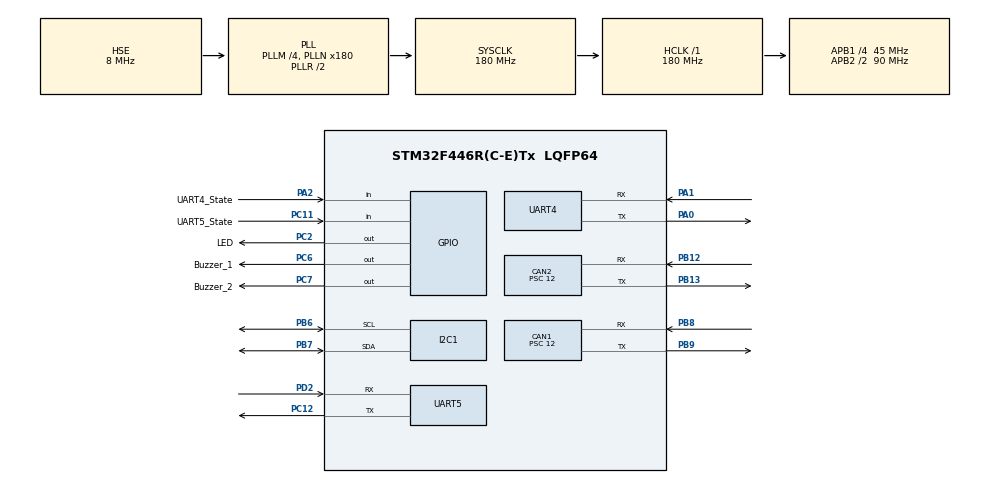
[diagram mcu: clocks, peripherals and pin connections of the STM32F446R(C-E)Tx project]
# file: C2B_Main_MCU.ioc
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CAN1.BS1=CAN_BS1_12TQ
CAN1.BS2=CAN_BS2_2TQ
CAN1.CalculateBaudRate=250000
CAN1.CalculateTimeBit=4000
CAN1.CalculateTimeQuantum=266.66666666666663
CAN1.Prescaler=12
CAN2.BS1=CAN_BS1_11TQ
CAN2.BS2=CAN_BS2_3TQ
CAN2.CalculateBaudRate=250000
CAN2.CalculateTimeBit=4000
CAN2.CalculateTimeQuantum=266.66666666666663
CAN2.Prescaler=12
Mcu.Family=STM32F4
Mcu.Name=STM32F446R(C-E)Tx
Mcu.Package=LQFP64
NVIC.CAN1_RX0_IRQn=true\:0\:0\:false\:false\:true\:true\:true\:true
NVIC.CAN1_RX1_IRQn=true\:0\:0\:false\:false\:true\:true\:true\:true
NVIC.CAN2_RX0_IRQn=true\:0\:0\:false\:false\:true\:true\:true\:true
NVIC.CAN2_RX1_IRQn=true\:0\:0\:false\:false\:true\:true\:true\:true
NVIC.I2C1_ER_IRQn=true\:0\:0\:false\:false\:true\:true\:true\:true
NVIC.I2C1_EV_IRQn=true\:0\:0\:false\:false\:true\:true\:true\:true
NVIC.PriorityGroup=NVIC_PRIORITYGROUP_4
NVIC.TIM8_TRG_COM_TIM14_IRQn=true\:0\:0\:false\:false\:true\:true\:true\:true
NVIC.UART4_IRQn=true\:0\:0\:false\:false\:true\:true\:true\:true
NVIC.UART5_IRQn=true\:0\:0\:false\:false\:true\:true\:true\:true
PA0-WKUP.Mode=Asynchronous
PA0-WKUP.Signal=UART4_TX
PA1.Mode=Asynchronous
PA1.Signal=UART4_RX
PA13.Mode=Serial_Wire
PA13.Signal=SYS_JTMS-SWDIO
PA14.Mode=Serial_Wire
PA14.Signal=SYS_JTCK-SWCLK
PA2.GPIO_Label=UART4_State
PA2.Signal=GPIO_Input
PB12.Mode=CAN_Activate
PB12.Signal=CAN2_RX
PB13.Mode=CAN_Activate
PB13.Signal=CAN2_TX
PB6.Mode=I2C
PB6.Signal=I2C1_SCL
PB7.Mode=I2C
PB7.Signal=I2C1_SDA
PB8.Mode=CAN_Activate
PB8.Signal=CAN1_RX
PB9.Mode=CAN_Activate
PB9.Signal=CAN1_TX
PC11.GPIO_Label=UART5_State
PC11.Signal=GPIO_Input
PC12.Mode=Asynchronous
PC12.Signal=UART5_TX
PC14-OSC32_IN.Mode=LSE-External-Oscillator
PC14-OSC32_IN.Signal=RCC_OSC32_IN
PC15-OSC32_OUT.Mode=LSE-External-Oscillator
PC15-OSC32_OUT.Signal=RCC_OSC32_OUT
PC2.GPIO_Label=LED
PC2.GPIO_Speed=GPIO_SPEED_FREQ_MEDIUM
PC2.Signal=GPIO_Output
PC6.GPIO_Label=Buzzer_1
PC6.Signal=GPIO_Output
PC7.GPIO_Label=Buzzer_2
PC7.Signal=GPIO_Output
PD2.Mode=Asynchronous
PD2.Signal=UART5_RX
PH0-OSC_IN.Mode=HSE-External-Oscillator
PH0-OSC_IN.Signal=RCC_OSC_IN
PH1-OSC_OUT.Mode=HSE-External-Oscillator
PH1-OSC_OUT.Signal=RCC_OSC_OUT
ProjectManager.HeapSize=0x200
ProjectManager.StackSize=0x400
ProjectManager.TargetToolchain=MDK-ARM V5.32
RCC.AHBFreq_Value=180000000
RCC.APB1CLKDivider=RCC_HCLK_DIV4
RCC.APB1Freq_Value=45000000
RCC.APB1TimFreq_Value=90000000
RCC.APB2CLKDivider=RCC_HCLK_DIV2
RCC.APB2Freq_Value=90000000
RCC.APB2TimFreq_Value=180000000
RCC.CortexFreq_Value=180000000
RCC.HCLKFreq_Value=180000000
RCC.HSE_VALUE=8000000
RCC.PLLM=4
RCC.PLLN=180
RCC.PLLSourceVirtual=RCC_PLLSOURCE_HSE
RCC.SYSCLKFreq_VALUE=180000000
RCC.SYSCLKSource=RCC_SYSCLKSOURCE_PLLRCLK
RCC.USBFreq_Value=180000000
RCC.VCOOutputFreq_Value=360000000
TIM14.Period=1000-1
TIM14.Prescaler=9000-1
UART4.VirtualMode=Asynchronous
UART5.VirtualMode=Asynchronous
VP_TIM14_VS_ClockSourceINT.Mode=Enable_Timer
board=custom

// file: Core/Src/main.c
/* USER CODE BEGIN Header */
/**
  ******************************************************************************
  * @file           : main.c
  * @brief          : Main program body
  ******************************************************************************
  * @attention
  *
  * Copyright (c) 2024 STMicroelectronics.
  * All rights reserved.
  *
  * This software is licensed under terms that can be found in the LICENSE file
  * in the root directory of this software component.
  * If no LICENSE file comes with this software, it is provided AS-IS.
  *
  ******************************************************************************
  */
/* USER CODE END Header */
#include "main.h"

CAN_HandleTypeDef hcan1;
CAN_HandleTypeDef hcan2;

I2C_HandleTypeDef hi2c1;

TIM_HandleTypeDef htim14;

UART_HandleTypeDef huart4;
UART_HandleTypeDef huart5;

/* USER CODE BEGIN PV */
uint8_t Mode=1,Mode_Temp, Speed=1, Joystick=0,Joystick_Brake=0, Steering_Mode=1, Shearing=2, Skiffing=0, Side_Trimmer=0, Pot_Angle=90, Joystick_Temp=0, Shearing_Temp=0, Steering_Mode_Temp=1, BT_Steer_Temp=0, Prev_Joystick = 0, Speed_Temp = 0;
uint8_t BT_Rx[9];
/* USER CODE END PV */

void SystemClock_Config(void);
static void MX_GPIO_Init(void);
static void MX_CAN1_Init(void);
static void MX_CAN2_Init(void);
static void MX_UART4_Init(void);
static void MX_UART5_Init(void);
static void MX_TIM14_Init(void);
static void MX_I2C1_Init(void);

void Joystick_Reception(void);

int main(void)
{

  /* MCU Configuration--------------------------------------------------------*/

  /* Reset of all peripherals, Initializes the Flash interface and the Systick. */
  HAL_Init();

  /* Configure the system clock */
  SystemClock_Config();

  /* Initialize all configured peripherals */
  MX_GPIO_Init();
  MX_CAN1_Init();
  MX_CAN2_Init();
  MX_UART4_Init();
  MX_UART5_Init();
  MX_TIM14_Init();
  MX_I2C1_Init();

  /* Infinite loop */
  while (1)
  {

    /* USER CODE BEGIN 3 */
		Joystick_Reception();
  }
  /* USER CODE END 3 */
}

void SystemClock_Config(void)
{
  RCC_OscInitTypeDef RCC_OscInitStruct = {0};
  RCC_ClkInitTypeDef RCC_ClkInitStruct = {0};

  /** Configure the main internal regulator output voltage
  */
  __HAL_RCC_PWR_CLK_ENABLE();
  __HAL_PWR_VOLTAGESCALING_CONFIG(PWR_REGULATOR_VOLTAGE_SCALE1);

  /** Initializes the RCC Oscillators according to the specified parameters
  * in the RCC_OscInitTypeDef structure.
  */
  RCC_OscInitStruct.OscillatorType = RCC_OSCILLATORTYPE_HSE;
  RCC_OscInitStruct.HSEState = RCC_HSE_ON;
  RCC_OscInitStruct.PLL.PLLState = RCC_PLL_ON;
  RCC_OscInitStruct.PLL.PLLSource = RCC_PLLSOURCE_HSE;
  RCC_OscInitStruct.PLL.PLLM = 4;
  RCC_OscInitStruct.PLL.PLLN = 180;
  RCC_OscInitStruct.PLL.PLLP = RCC_PLLP_DIV2;
  RCC_OscInitStruct.PLL.PLLQ = 2;
  RCC_OscInitStruct.PLL.PLLR = 2;
  if (HAL_RCC_OscConfig(&RCC_OscInitStruct) != HAL_OK)
  {
    Error_Handler();
  }

  /** Activate the Over-Drive mode
  */
  if (HAL_PWREx_EnableOverDrive() != HAL_OK)
  {
    Error_Handler();
  }

  /** Initializes the CPU, AHB and APB buses clocks
  */
  RCC_ClkInitStruct.ClockType = RCC_CLOCKTYPE_HCLK|RCC_CLOCKTYPE_SYSCLK
                              |RCC_CLOCKTYPE_PCLK1|RCC_CLOCKTYPE_PCLK2;
  RCC_ClkInitStruct.SYSCLKSource = RCC_SYSCLKSOURCE_PLLRCLK;
  RCC_ClkInitStruct.AHBCLKDivider = RCC_SYSCLK_DIV1;
  RCC_ClkInitStruct.APB1CLKDivider = RCC_HCLK_DIV4;
  RCC_ClkInitStruct.APB2CLKDivider = RCC_HCLK_DIV2;

  if (HAL_RCC_ClockConfig(&RCC_ClkInitStruct, FLASH_LATENCY_5) != HAL_OK)
  {
    Error_Handler();
  }
}

static void MX_CAN1_Init(void)
{

  hcan1.Instance = CAN1;
  hcan1.Init.Prescaler = 12;
  hcan1.Init.Mode = CAN_MODE_NORMAL;
  hcan1.Init.SyncJumpWidth = CAN_SJW_1TQ;
  hcan1.Init.TimeSeg1 = CAN_BS1_12TQ;
  hcan1.Init.TimeSeg2 = CAN_BS2_2TQ;
  hcan1.Init.TimeTriggeredMode = DISABLE;
  hcan1.Init.AutoBusOff = DISABLE;
  hcan1.Init.AutoWakeUp = DISABLE;
  hcan1.Init.AutoRetransmission = DISABLE;
  hcan1.Init.ReceiveFifoLocked = DISABLE;
  hcan1.Init.TransmitFifoPriority = DISABLE;
  if (HAL_CAN_Init(&hcan1) != HAL_OK)
  {
    Error_Handler();
  }

}

static void MX_CAN2_Init(void)
{

  hcan2.Instance = CAN2;
  hcan2.Init.Prescaler = 12;
  hcan2.Init.Mode = CAN_MODE_NORMAL;
  hcan2.Init.SyncJumpWidth = CAN_SJW_1TQ;
  hcan2.Init.TimeSeg1 = CAN_BS1_11TQ;
  hcan2.Init.TimeSeg2 = CAN_BS2_3TQ;
  hcan2.Init.TimeTriggeredMode = DISABLE;
  hcan2.Init.AutoBusOff = DISABLE;
  hcan2.Init.AutoWakeUp = DISABLE;
  hcan2.Init.AutoRetransmission = DISABLE;
  hcan2.Init.ReceiveFifoLocked = DISABLE;
  hcan2.Init.TransmitFifoPriority = DISABLE;
  if (HAL_CAN_Init(&hcan2) != HAL_OK)
  {
    Error_Handler();
  }

}

static void MX_I2C1_Init(void)
{

  hi2c1.Instance = I2C1;
  hi2c1.Init.ClockSpeed = 100000;
  hi2c1.Init.DutyCycle = I2C_DUTYCYCLE_2;
  hi2c1.Init.OwnAddress1 = 0;
  hi2c1.Init.AddressingMode = I2C_ADDRESSINGMODE_7BIT;
  hi2c1.Init.DualAddressMode = I2C_DUALADDRESS_DISABLE;
  hi2c1.Init.OwnAddress2 = 0;
  hi2c1.Init.GeneralCallMode = I2C_GENERALCALL_DISABLE;
  hi2c1.Init.NoStretchMode = I2C_NOSTRETCH_DISABLE;
  if (HAL_I2C_Init(&hi2c1) != HAL_OK)
  {
    Error_Handler();
  }

}

static void MX_TIM14_Init(void)
{

  htim14.Instance = TIM14;
  htim14.Init.Prescaler = 9000-1;
  htim14.Init.CounterMode = TIM_COUNTERMODE_UP;
  htim14.Init.Period = 1000-1;
  htim14.Init.ClockDivision = TIM_CLOCKDIVISION_DIV1;
  htim14.Init.AutoReloadPreload = TIM_AUTORELOAD_PRELOAD_DISABLE;
  if (HAL_TIM_Base_Init(&htim14) != HAL_OK)
  {
    Error_Handler();
  }

}

static void MX_UART4_Init(void)
{

  huart4.Instance = UART4;
  huart4.Init.BaudRate = 115200;
  huart4.Init.WordLength = UART_WORDLENGTH_8B;
  huart4.Init.StopBits = UART_STOPBITS_1;
  huart4.Init.Parity = UART_PARITY_NONE;
  huart4.Init.Mode = UART_MODE_TX_RX;
  huart4.Init.HwFlowCtl = UART_HWCONTROL_NONE;
  huart4.Init.OverSampling = UART_OVERSAMPLING_16;
  if (HAL_UART_Init(&huart4) != HAL_OK)
  {
    Error_Handler();
  }

}

static void MX_UART5_Init(void)
{

  huart5.Instance = UART5;
  huart5.Init.BaudRate = 115200;
  huart5.Init.WordLength = UART_WORDLENGTH_8B;
  huart5.Init.StopBits = UART_STOPBITS_1;
  huart5.Init.Parity = UART_PARITY_NONE;
  huart5.Init.Mode = UART_MODE_TX_RX;
  huart5.Init.HwFlowCtl = UART_HWCONTROL_NONE;
  huart5.Init.OverSampling = UART_OVERSAMPLING_16;
  if (HAL_UART_Init(&huart5) != HAL_OK)
  {
    Error_Handler();
  }

}

static void MX_GPIO_Init(void)
{
  GPIO_InitTypeDef GPIO_InitStruct = {0};

  /* GPIO Ports Clock Enable */
  __HAL_RCC_GPIOC_CLK_ENABLE();
  __HAL_RCC_GPIOH_CLK_ENABLE();
  __HAL_RCC_GPIOA_CLK_ENABLE();
  __HAL_RCC_GPIOB_CLK_ENABLE();
  __HAL_RCC_GPIOD_CLK_ENABLE();

  /*Configure GPIO pin Output Level */
  HAL_GPIO_WritePin(GPIOC, LED_Pin|Buzzer_1_Pin|Buzzer_2_Pin, GPIO_PIN_RESET);

  /*Configure GPIO pin : LED_Pin */
  GPIO_InitStruct.Pin = LED_Pin;
  GPIO_InitStruct.Mode = GPIO_MODE_OUTPUT_PP;
  GPIO_InitStruct.Pull = GPIO_NOPULL;
  GPIO_InitStruct.Speed = GPIO_SPEED_FREQ_MEDIUM;
  HAL_GPIO_Init(LED_GPIO_Port, &GPIO_InitStruct);

  /*Configure GPIO pin : UART4_State_Pin */
  GPIO_InitStruct.Pin = UART4_State_Pin;
  GPIO_InitStruct.Mode = GPIO_MODE_INPUT;
  GPIO_InitStruct.Pull = GPIO_NOPULL;
  HAL_GPIO_Init(UART4_State_GPIO_Port, &GPIO_InitStruct);

  /*Configure GPIO pins : Buzzer_1_Pin Buzzer_2_Pin */
  GPIO_InitStruct.Pin = Buzzer_1_Pin|Buzzer_2_Pin;
  GPIO_InitStruct.Mode = GPIO_MODE_OUTPUT_PP;
  GPIO_InitStruct.Pull = GPIO_NOPULL;
  GPIO_InitStruct.Speed = GPIO_SPEED_FREQ_LOW;
  HAL_GPIO_Init(GPIOC, &GPIO_InitStruct);

  /*Configure GPIO pin : UART5_State_Pin */
  GPIO_InitStruct.Pin = UART5_State_Pin;
  GPIO_InitStruct.Mode = GPIO_MODE_INPUT;
  GPIO_InitStruct.Pull = GPIO_NOPULL;
  HAL_GPIO_Init(UART5_State_GPIO_Port, &GPIO_InitStruct);

}

/* USER CODE BEGIN 4 */
void Joystick_Reception(void)
{
	//Joy_Loop++;
//	BT_State=BT_STATED_READ;

	if ((BT_Rx[0] == 0xAA ) &&	( BT_Rx[7] == 0xFF ))
	{
		Mode 						 = BT_Rx[1];
		Speed 					 = BT_Rx[2]  != 0 ? BT_Rx[2] : Speed ;
		Steering_Mode 	 = BT_Rx[3];
		Pot_Angle 			 = BT_Rx[4];
		Joystick 				 = BT_Rx[5];
		Shearing				 = BT_Rx[6];
	}
}
/* USER CODE END 4 */

void Error_Handler(void)
{
  __disable_irq();
  while (1)
  {
  }
}
